# CY8C5888LTI_LP097 register map
File version: 0.1
CY8C58LP
Registers are 8-bit, read-write, no defined reset value unless marked. A register's access mark holds for its fields unless they carry their own. Offsets are from the block's base; lines under a group give offsets from that group; [hi:lo] are bit positions; {n}, {i} and the like mark numbered series; 'fields as' and 'values as' point back to an identical list; <NAME> marks a mode.

## Memory map
0x00000000 PWMSend
0x00000000 PWMHBro
0x00000000 PWMServo
0x00000000 steeringTimer
0x00000000 UART
0x00000000 throttleTimer

## PWMSend
Base 0x00000000
0x4000642A PWMSend_COMPARE_Reg 16-bit — UDB.D0 - Assigned Compare Value
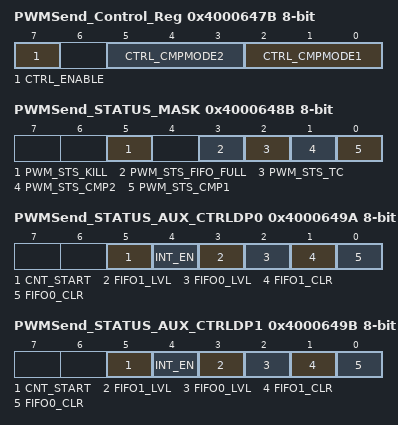
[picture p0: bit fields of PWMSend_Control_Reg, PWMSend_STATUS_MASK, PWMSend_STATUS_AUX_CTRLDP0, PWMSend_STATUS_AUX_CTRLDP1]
0x4000647B PWMSend_Control_Reg — UDB Control Register - Assigned Control Register Value
  [7] CTRL_ENABLE — Enable the PWM
  [5:3] CTRL_CMPMODE2 — Compare mode 2
  [2:0] CTRL_CMPMODE1 — Compare mode 1
0x4000648B PWMSend_STATUS_MASK — UDB Status bits Interrupt Mask Enable Register
  [5] PWM_STS_KILL ro — Enables the Interrupt on Kill
  [3] PWM_STS_FIFO_FULL ro — FIFO Full Status Mask
  [2] PWM_STS_TC ro — Enables the Interrupt on Terminal Count
  [1] PWM_STS_CMP2 ro — Enables the Interrupt on Compare 2
  [0] PWM_STS_CMP1 ro — Enables the Interrupt on Compare 1
0x4000649A PWMSend_STATUS_AUX_CTRLDP0 — UDB Auxilliary Control Register
  [5] CNT_START — FIFO0 clear
    0=E_CNT_START0 (Disable counter); 1=E_CNT_START1 (Enable counter)
  [4] INT_EN
    0=E_INT_EN0 (Interrupt disabled); 1=E_INT_EN1 (Interrupt enabled)
  [3] FIFO1_LVL — FIFO level
    0=E_FIFO_LVL_0 (FIFO LVL: input mode: FIFO not full; output mode: FIFO not empty); 1=E_FIFO_LVL_1 (FIFO LVL: input mode: FIFO at least 1/2 empty; output mode: FIFO at least 1/2 full)
  [2] FIFO0_LVL — FIFO level
    values as FIFO1_LVL
  [1] FIFO1_CLR — FIFO1 clear
    0=E_FIFO_CLR_0 (Normal FIFO operation); 1=E_FIFO_CLR_1 (Clear FIFO state)
  [0] FIFO0_CLR — FIFO0 clear
    values as FIFO1_CLR
0x4000649B PWMSend_STATUS_AUX_CTRLDP1 — UDB Auxilliary Control Register
  fields as PWMSend_STATUS_AUX_CTRLDP0

## PWMHBro
Base 0x00000000
0x4000642D PWMHBro__COMPARE1 — UDB.D0 - Assigned Compare1 Value
0x4000643D PWMHBro__COMPARE2 — UDB.D1 - Assigned Compare2 Value
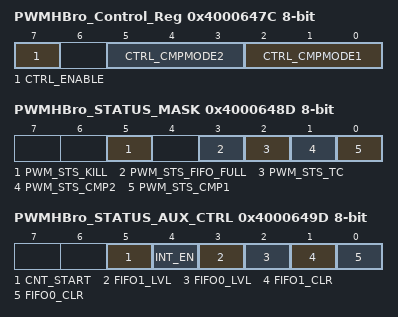
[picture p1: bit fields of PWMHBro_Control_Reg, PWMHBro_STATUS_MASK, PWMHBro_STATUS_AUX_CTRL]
0x4000647C PWMHBro_Control_Reg — UDB Control Register - Assigned Control Register Value
  [7] CTRL_ENABLE — Enable the PWM
  [5:3] CTRL_CMPMODE2 — Compare mode 2
  [2:0] CTRL_CMPMODE1 — Compare mode 1
0x4000648D PWMHBro_STATUS_MASK — UDB Status bits Interrupt Mask Enable Register
  fields as PWMSend.PWMSend_STATUS_MASK
0x4000649D PWMHBro_STATUS_AUX_CTRL — UDB Auxilliary Control Register
  fields as PWMSend.PWMSend_STATUS_AUX_CTRLDP0

## PWMServo
Base 0x00000000
0x4000642E PWMServo_COMPARE_Reg 16-bit — UDB.D0 - Assigned Compare Value
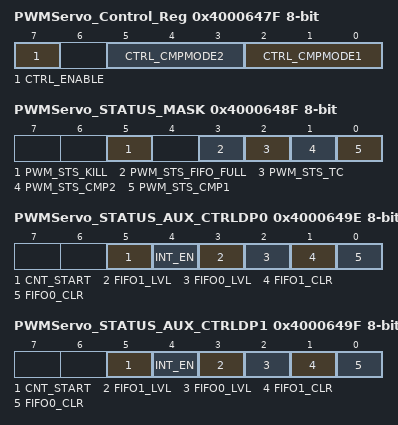
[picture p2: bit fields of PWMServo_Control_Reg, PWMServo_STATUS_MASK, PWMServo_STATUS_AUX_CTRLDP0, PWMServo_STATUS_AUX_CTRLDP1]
0x4000647F PWMServo_Control_Reg — UDB Control Register - Assigned Control Register Value
  [7] CTRL_ENABLE — Enable the PWM
  [5:3] CTRL_CMPMODE2 — Compare mode 2
  [2:0] CTRL_CMPMODE1 — Compare mode 1
0x4000648F PWMServo_STATUS_MASK — UDB Status bits Interrupt Mask Enable Register
  fields as PWMSend.PWMSend_STATUS_MASK
0x4000649E PWMServo_STATUS_AUX_CTRLDP0 — UDB Auxilliary Control Register
  fields as PWMSend.PWMSend_STATUS_AUX_CTRLDP0
0x4000649F PWMServo_STATUS_AUX_CTRLDP1 — UDB Auxilliary Control Register
  fields as PWMSend.PWMSend_STATUS_AUX_CTRLDP0

## steeringTimer
Base 0x00000000
0x40006404 steeringTimer_COUNTER 16-bit — UDB.A0 - Current Down Counter Value
0x40006424 steeringTimer_PERIOD 16-bit — UDB.D0 - Assigned Period
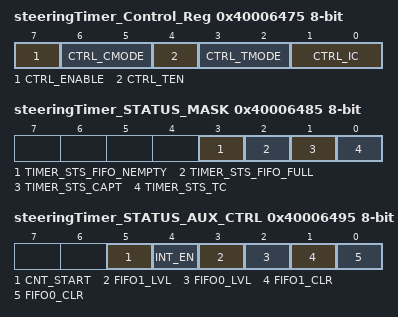
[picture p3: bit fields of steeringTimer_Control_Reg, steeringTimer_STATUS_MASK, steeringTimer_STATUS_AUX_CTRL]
0x40006475 steeringTimer_Control_Reg — UDB Control Register - Assigned Control Register Value
  [7] CTRL_ENABLE — Enable the Timer
  [6:5] CTRL_CMODE — Capture Mode
  [4] CTRL_TEN — Trigger Enable Bit
  [3:2] CTRL_TMODE — Trigger Mode
  [1:0] CTRL_IC — Interrupt Count
0x40006485 steeringTimer_STATUS_MASK — UDB Status bits Interrupt Mask Enable Register
  [3] TIMER_STS_FIFO_NEMPTY ro — FIFO Empty status
  [2] TIMER_STS_FIFO_FULL ro — FIFO Full Status
  [1] TIMER_STS_CAPT ro — Enables the Interrupt on Capture
  [0] TIMER_STS_TC ro — Enables the Interrupt on TC
0x40006495 steeringTimer_STATUS_AUX_CTRL — UDB Auxilliary Control Register
  fields as PWMSend.PWMSend_STATUS_AUX_CTRLDP0

## UART
Base 0x00000000
0x40006449 TX_UART_TX_DATA — TX Data Register
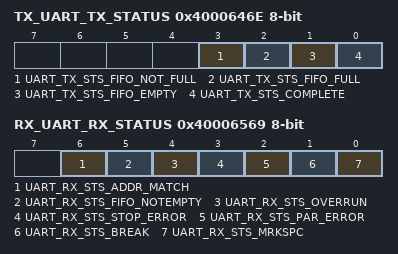
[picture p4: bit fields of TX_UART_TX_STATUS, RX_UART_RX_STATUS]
0x4000646E TX_UART_TX_STATUS — TX status register
  [3] UART_TX_STS_FIFO_NOT_FULL ro, [2] UART_TX_STS_FIFO_FULL ro, [1] UART_TX_STS_FIFO_EMPTY ro, [0] UART_TX_STS_COMPLETE ro
0x4000652A RX_UART_RX_ADDRESS1 — RX Address1 Register
0x4000653A RX_UART_RX_ADDRESS2 — RX Address2 Register
0x4000654A RX_UART_RX_DATA — RX Data Register
0x40006569 RX_UART_RX_STATUS — RX status register
  [6] UART_RX_STS_ADDR_MATCH ro, [5] UART_RX_STS_FIFO_NOTEMPTY ro, [4] UART_RX_STS_OVERRUN ro, [3] UART_RX_STS_STOP_ERROR ro, [2] UART_RX_STS_PAR_ERROR ro, [1] UART_RX_STS_BREAK ro, [0] UART_RX_STS_MRKSPC ro

## throttleTimer
Base 0x00000000
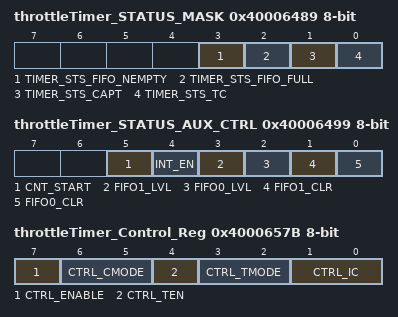
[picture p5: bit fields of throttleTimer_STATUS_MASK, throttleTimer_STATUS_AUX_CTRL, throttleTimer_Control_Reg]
0x40006489 throttleTimer_STATUS_MASK — UDB Status bits Interrupt Mask Enable Register
  fields as steeringTimer.steeringTimer_STATUS_MASK
0x40006499 throttleTimer_STATUS_AUX_CTRL — UDB Auxilliary Control Register
  fields as PWMSend.PWMSend_STATUS_AUX_CTRLDP0
0x40006508 throttleTimer_COUNTER 16-bit — UDB.A0 - Current Down Counter Value
0x40006528 throttleTimer_PERIOD 16-bit — UDB.D0 - Assigned Period
0x4000657B throttleTimer_Control_Reg — UDB Control Register - Assigned Control Register Value
  [7] CTRL_ENABLE — Enable the Timer
  [6:5] CTRL_CMODE — Capture Mode
  [4] CTRL_TEN — Trigger Enable Bit
  [3:2] CTRL_TMODE — Trigger Mode
  [1:0] CTRL_IC — Interrupt Count
